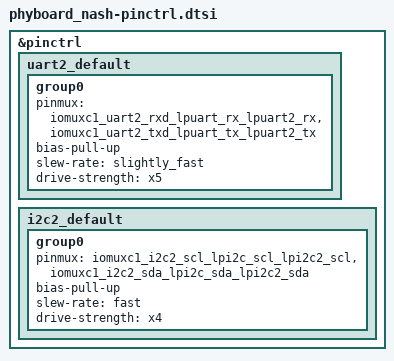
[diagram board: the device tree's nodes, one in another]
/*
 * Copyright 2024 PHYTEC Messtechnik GmbH
 *
 * SPDX-License-Identifier: Apache-2.0
 */

#include <nxp/nxp_imx/mimx9352cvuxk-pinctrl.dtsi>

&pinctrl {
	uart2_default: uart2_default {
		group0 {
			pinmux = <&iomuxc1_uart2_rxd_lpuart_rx_lpuart2_rx>,
				<&iomuxc1_uart2_txd_lpuart_tx_lpuart2_tx>;
			bias-pull-up;
			slew-rate = "slightly_fast";
			drive-strength = "x5";
		};
	};

	i2c2_default: i2c2_default {
		group0 {
			pinmux = <&iomuxc1_i2c2_scl_lpi2c_scl_lpi2c2_scl>,
				<&iomuxc1_i2c2_sda_lpi2c_sda_lpi2c2_sda>;
			bias-pull-up;
			slew-rate = "fast";
			drive-strength = "x4";
		};
	};
};
